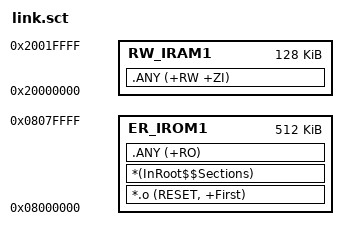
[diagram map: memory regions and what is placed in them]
; *************************************************************
; *** Scatter-Loading Description File generated by uVision ***
; *************************************************************

LR_IROM1 0x08000000 0x00080000  {    ; load region size_region (GD32G553: 512KB Flash)
  ER_IROM1 0x08000000 0x00080000  {  ; load address = execution address
   *.o (RESET, +First)
   *(InRoot$$Sections)
   .ANY (+RO)
  }
  RW_IRAM1 0x20000000 0x00020000  {  ; RW data (GD32G553: 128KB SRAM)
   .ANY (+RW +ZI)
  }
}

